AUTOSAR XML (schema 4-0-3)
standard types defined: Boolean, UInt8
package /AUTOSAR_Platform/DataConstrs
  range DC_Boolean: raw 0..1
package /PATAC/Facility/DataTypes/Implementation
  unit NoUnit: factor-si-to-unit=1, offset-si-to-unit=0
package /PATAC/MSM/ComponentTypes
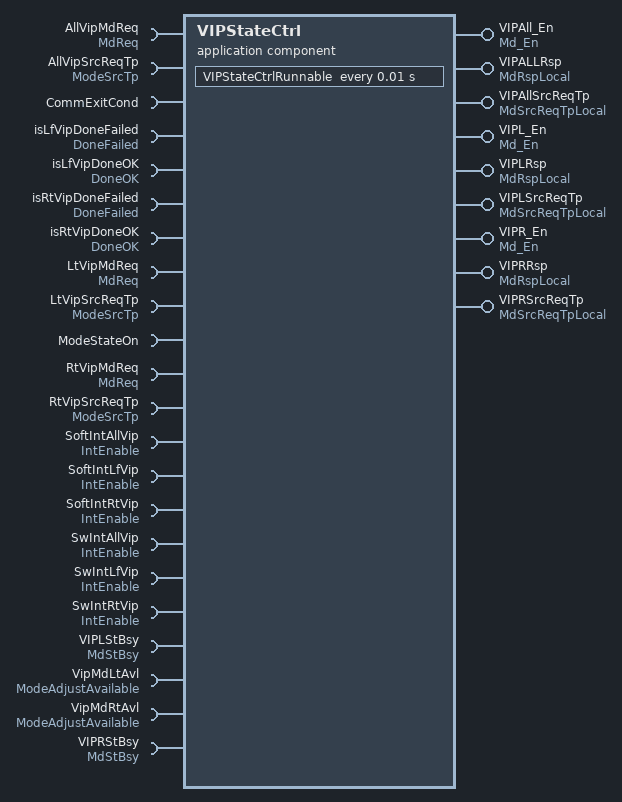
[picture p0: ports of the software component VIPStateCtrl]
  application sw component type VIPStateCtrl
    9 x provide port:
      VIPAll_En: nonqueued-sender-com-spec{data-element=Md_En/Val, init-value=0}, provided-interface=Md_En
      VIPALLRsp: nonqueued-sender-com-spec{data-element=MdRspLocal/Val, init-value=0}, provided-interface=MdRspLocal
      VIPAllSrcReqTp: nonqueued-sender-com-spec{data-element=MdSrcReqTpLocal/Val, init-value=0}, provided-interface=MdSrcReqTpLocal
      VIPL_En: nonqueued-sender-com-spec{data-element=Md_En/Val, init-value=0}, provided-interface=Md_En
      VIPLRsp: nonqueued-sender-com-spec{data-element=MdRspLocal/Val, init-value=0}, provided-interface=MdRspLocal
      VIPLSrcReqTp: nonqueued-sender-com-spec{data-element=MdSrcReqTpLocal/Val, init-value=0}, provided-interface=MdSrcReqTpLocal
      VIPR_En: nonqueued-sender-com-spec{data-element=Md_En/Val, init-value=0}, provided-interface=Md_En
      VIPRRsp: nonqueued-sender-com-spec{data-element=MdRspLocal/Val, init-value=0}, provided-interface=MdRspLocal
      VIPRSrcReqTp: nonqueued-sender-com-spec{data-element=MdSrcReqTpLocal/Val, init-value=0}, provided-interface=MdSrcReqTpLocal
    22 x require port:
      AllVipMdReq: nonqueued-receiver-com-spec{data-element=MdReq/Val, filter=data-filter-type=ALWAYS, init-value=0}, required-interface=MdReq
      AllVipSrcReqTp: nonqueued-receiver-com-spec{data-element=ModeSrcTp/Val, filter=data-filter-type=ALWAYS, init-value=0}, required-interface=ModeSrcTp
      CommExitCond: nonqueued-receiver-com-spec{data-element=CommExitCond/Val, filter=data-filter-type=ALWAYS, init-value=0}, required-interface=CommExitCond
      isLfVipDoneFailed: nonqueued-receiver-com-spec{data-element=DoneFailed/Val, filter=data-filter-type=ALWAYS, init-value=0}, required-interface=DoneFailed
      isLfVipDoneOK: nonqueued-receiver-com-spec{data-element=DoneOK/Val, filter=data-filter-type=ALWAYS, init-value=0}, required-interface=DoneOK
      isRtVipDoneFailed: nonqueued-receiver-com-spec{data-element=DoneFailed/Val, filter=data-filter-type=ALWAYS, init-value=0}, required-interface=DoneFailed
      isRtVipDoneOK: nonqueued-receiver-com-spec{data-element=DoneOK/Val, filter=data-filter-type=ALWAYS, init-value=0}, required-interface=DoneOK
      LtVipMdReq: nonqueued-receiver-com-spec{data-element=MdReq/Val, filter=data-filter-type=ALWAYS, init-value=0}, required-interface=MdReq
      LtVipSrcReqTp: nonqueued-receiver-com-spec{data-element=ModeSrcTp/Val, filter=data-filter-type=ALWAYS, init-value=0}, required-interface=ModeSrcTp
      ModeStateOn: nonqueued-receiver-com-spec{data-element=ModeStateOn/Val, filter=data-filter-type=ALWAYS, init-value=0}, required-interface=ModeStateOn
      RtVipMdReq: nonqueued-receiver-com-spec{data-element=MdReq/Val, filter=data-filter-type=ALWAYS, init-value=0}, required-interface=MdReq
      RtVipSrcReqTp: nonqueued-receiver-com-spec{data-element=ModeSrcTp/Val, filter=data-filter-type=ALWAYS, init-value=0}, required-interface=ModeSrcTp
      SoftIntAllVip: nonqueued-receiver-com-spec{data-element=IntEnable/Val, filter=data-filter-type=ALWAYS, init-value=0}, required-interface=IntEnable
      SoftIntLfVip: nonqueued-receiver-com-spec{data-element=IntEnable/Val, filter=data-filter-type=ALWAYS, init-value=0}, required-interface=IntEnable
      SoftIntRtVip: nonqueued-receiver-com-spec{data-element=IntEnable/Val, filter=data-filter-type=ALWAYS, init-value=0}, required-interface=IntEnable
      SwIntAllVip: nonqueued-receiver-com-spec{data-element=IntEnable/Val, filter=data-filter-type=ALWAYS, init-value=0}, required-interface=IntEnable
      SwIntLfVip: nonqueued-receiver-com-spec{data-element=IntEnable/Val, filter=data-filter-type=ALWAYS, init-value=0}, required-interface=IntEnable
      SwIntRtVip: nonqueued-receiver-com-spec{data-element=IntEnable/Val, filter=data-filter-type=ALWAYS, init-value=0}, required-interface=IntEnable
      VIPLStBsy: nonqueued-receiver-com-spec{data-element=MdStBsy/Val, filter=data-filter-type=ALWAYS, init-value=0}, required-interface=MdStBsy
      VipMdLtAvl: nonqueued-receiver-com-spec{data-element=ModeAdjustAvailable/Val, filter=data-filter-type=ALWAYS, init-value=0}, required-interface=ModeAdjustAvailable
      VipMdRtAvl: nonqueued-receiver-com-spec{data-element=ModeAdjustAvailable/Val, filter=data-filter-type=ALWAYS, init-value=0}, required-interface=ModeAdjustAvailable
      VIPRStBsy: nonqueued-receiver-com-spec{data-element=MdStBsy/Val, filter=data-filter-type=ALWAYS, init-value=0}, required-interface=MdStBsy
    behavior VIPStateCtrl_InternalBehavior
      timing event TMT_EZEStateCtrlRunnable: start-on-event=VIPStateCtrlRunnable, period=0.01
      runnable VIPStateCtrlRunnable
        data-receive-point-by-arguments:
          22 x access:
            REC_AllVipMdReq_Val: accessed-variable=AllVipMdReq.Val
            REC_AllVipSrcReqTp_Val: accessed-variable=AllVipSrcReqTp.Val
            REC_CommExitCond_Val: accessed-variable=CommExitCond.Val
            REC_EZEStBsy_Val: accessed-variable=VIPLStBsy.Val
            REC_isLfVipDoneFailed_Val: accessed-variable=isLfVipDoneFailed.Val
            REC_isLfVipDoneOK_Val: accessed-variable=isLfVipDoneOK.Val
            REC_isRtVipDoneFailed_Val: accessed-variable=isRtVipDoneFailed.Val
            REC_isRtVipDoneOK_Val: accessed-variable=isRtVipDoneOK.Val
            REC_LtVipMdReq_Val: accessed-variable=LtVipMdReq.Val
            REC_LtVipSrcReqTp_Val: accessed-variable=LtVipSrcReqTp.Val
            REC_ModeStateOn_Val: accessed-variable=ModeStateOn.Val
            REC_RtVipMdReq_Val: accessed-variable=RtVipMdReq.Val
            REC_RtVipSrcReqTp_Val: accessed-variable=RtVipSrcReqTp.Val
            REC_SoftIntAllVip_Val: accessed-variable=SoftIntAllVip.Val
            REC_SoftIntLfVip_Val: accessed-variable=SoftIntLfVip.Val
            REC_SoftIntRtVip_Val: accessed-variable=SoftIntRtVip.Val
            REC_SwIntAllVip_Val: accessed-variable=SwIntAllVip.Val
            REC_SwIntLfVip_Val: accessed-variable=SwIntLfVip.Val
            REC_SwIntRtVip_Val: accessed-variable=SwIntRtVip.Val
            REC_VipMdLtAvl_Val: accessed-variable=VipMdLtAvl.Val
            REC_VipMdRtAvl_Val: accessed-variable=VipMdRtAvl.Val
            REC_VIPRStBsy_Val: accessed-variable=VIPRStBsy.Val
        data-send-points:
          9 x access:
            SEND_EZQ_En_Val: accessed-variable=VIPL_En.Val
            SEND_EZQRsp_Val: accessed-variable=VIPLRsp.Val
            SEND_EZQSrcReqTp_Val: accessed-variable=VIPLSrcReqTp.Val
            SEND_VIPAll_En_Val: accessed-variable=VIPAll_En.Val
            SEND_VIPALLRsp_Val: accessed-variable=VIPALLRsp.Val
            SEND_VIPAllSrcReqTp_Val: accessed-variable=VIPAllSrcReqTp.Val
            SEND_VIPR_En_Val: accessed-variable=VIPR_En.Val
            SEND_VIPRRsp_Val: accessed-variable=VIPRRsp.Val
            SEND_VIPRSrcReqTp_Val: accessed-variable=VIPRSrcReqTp.Val
  swc implementation VIPStateCtrl_Implementation: behavior=VIPStateCtrl_InternalBehavior
    code-descriptors:
      code Default: artifact-descriptors=autosar-engineering-object={short-label=Default, category=SWSRC}
package /PATAC/MSM/DataTypes/ImplementationDataTypes
  impl type IntEnable: category=VALUE, base-type=Boolean, sw-calibration-access=READ-ONLY, type-emitter=RTE
package /PATAC/MSM/ModeAdjust/DataType
  impl type MdRspLocal1: category=VALUE, base-type=UInt8, sw-calibration-access=READ-ONLY, compu {0=MdRsp_None, 1=MdRsp_RecallSuccessfully, 2=MdRsp_RecallUnsuccessfully_LocalInterrupt, 3=MdRsp_RecallUnsuccessfully_Error, 4=MdRsp_RecallOngoing, 5=MdRsp_RecallHalt}, type-emitter=RTE
  impl type SrcReqTp1: category=VALUE, base-type=UInt8, sw-calibration-access=READ-ONLY, compu {0=SrcReqTp_None, 1=SrcReqTp_Local, 2=SrcReqTp_HMI2L, 3=SrcReqTp_HMI2R, 4=SrcReqTp_HMI, 5=SrcReqTp_Remote, 6=SrcReqTp_SRS}, type-emitter=RTE
package /PATAC/MSM/ModeAdjust/PortInterface
  12 x sender receiver interface:
    CommExitCond: invalidation-policy{data-element=CommExitCond/Val, handle-invalid=DONT-INVALIDATE}
      data Val: type=Boolean
    DoneFailed: invalidation-policy{data-element=DoneFailed/Val, handle-invalid=DONT-INVALIDATE}
      data Val: type=Boolean
    DoneOK: invalidation-policy{data-element=DoneOK/Val, handle-invalid=DONT-INVALIDATE}
      data Val: type=Boolean
    IntEnable: invalidation-policy{data-element=IntEnable/Val, handle-invalid=DONT-INVALIDATE}
      data Val: type=IntEnable
    Md_En: invalidation-policy{data-element=Md_En/Val, handle-invalid=DONT-INVALIDATE}
      data Val: type=Boolean
    MdReq: invalidation-policy{data-element=MdReq/Val, handle-invalid=DONT-INVALIDATE}
      data Val: type=Boolean
    MdRspLocal: invalidation-policy{data-element=MdRspLocal/Val, handle-invalid=DONT-INVALIDATE}
      data Val: type=MdRspLocal1
    MdSrcReqTpLocal: invalidation-policy{data-element=MdSrcReqTpLocal/Val, handle-invalid=DONT-INVALIDATE}
      data Val: type=SrcReqTp1
    MdStBsy: invalidation-policy{data-element=MdStBsy/Val, handle-invalid=DONT-INVALIDATE}
      data Val: type=Boolean
    ModeAdjustAvailable: invalidation-policy{data-element=ModeAdjustAvailable/Val, handle-invalid=DONT-INVALIDATE}
      data Val: type=Boolean
    ModeSrcTp: invalidation-policy{data-element=ModeSrcTp/Val, handle-invalid=DONT-INVALIDATE}
      data Val: type=SrcReqTp1
    ModeStateOn: invalidation-policy{data-element=ModeStateOn/Val, handle-invalid=DONT-INVALIDATE}
      data Val: type=Boolean
